# CM_CORE_AON__EVE3 register map
Vendor: Texas Instruments
Peripheral module from a debugger description file (folder TDA2Px).
Registers are 32-bit, access per field, reset 0x3 unless marked. A register's access mark holds for its fields unless they carry their own. Offsets are as the file gives them; lines under a group give offsets from that group; [hi:lo] are bit positions; {n}, {i} and the like mark numbered series; 'fields as' and 'values as' point back to an identical list; <NAME> marks a mode.

## CM_CORE_AON__EVE3
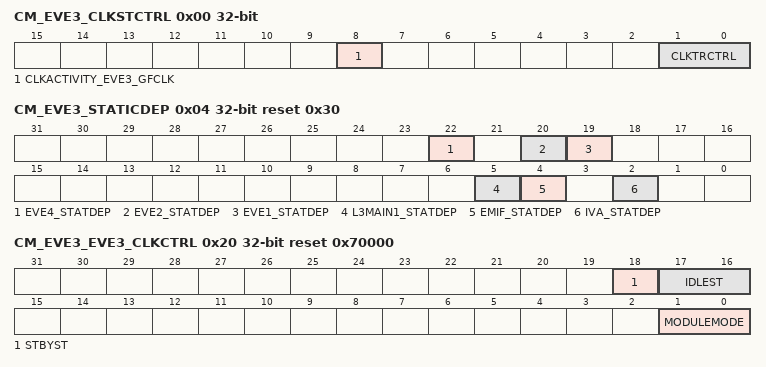
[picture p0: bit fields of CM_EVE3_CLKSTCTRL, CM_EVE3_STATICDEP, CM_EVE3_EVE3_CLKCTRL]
0x00 CM_EVE3_CLKSTCTRL — This register enables the EVE domain power state transition. It controls the HW supervised domain power state transition between ON-ACTIVE and ON-INACTIVE states. It also hold one status bit per clock input of the domain.
  [8] CLKACTIVITY_EVE3_GFCLK ro — This field indicates the state of the EVE3_GFCLK clock in the domain. [warm reset insensitive]EVE3_GFCLK clock is used as one of the source clocks to the ISS module in this family of devices.
    0=INACT (Corresponding clock is definitely gated); 1=ACT (Corresponding clock is running or gating/ungating transition is on-going)
  [1:0] CLKTRCTRL rw — Controls the clock state transition of the DSP clock domain.
    0=NO_SLEEP (NO_SLEEP: Sleep transition cannot be initiated. Wakeup transition may however occur.); 1=SW_SLEEP (SW_SLEEP: Start a software forced sleep transition on the domain.); 2=SW_WKUP (SW_WKUP: Start a software forced wake-up transition on the domain.); 3=HW_AUTO (HW_AUTO: Automatic transition is enabled. Sleep and wakeup transition are based upon hardware conditions.)
0x04 CM_EVE3_STATICDEP reset 0x30 — This register controls the static domain depedencies from EVE3 domain towards 'target' domains. It is relevant only for domain having system initiator(s).EVE3 is not supported in this family of devices.
  [22] EVE4_STATDEP rw — Static dependency towards EVE4 clock domainEVE4 is not supported in this family of devices.
    0=DISABLED (Dependency is disabled); 1=ENABLED (Dependency is enabled)
  [20] EVE2_STATDEP rw — Static dependency towards EVE2 clock domain
    values as EVE4_STATDEP
  [19] EVE1_STATDEP rw — Static dependency towards EVE1 clock domain
    values as EVE4_STATDEP
  [5] L3MAIN1_STATDEP ro — Static dependency towards L3MAIN1 clock domain
    1=ENABLED (Dependency is enabled)
  [4] EMIF_STATDEP rw — Static dependency towards EMIF clock domain
    values as EVE4_STATDEP
  [2] IVA_STATDEP rw — Static dependency towards IVA clock domain
    values as EVE4_STATDEP
0x20 CM_EVE3_EVE3_CLKCTRL reset 0x70000 — This register manages the ISS clocks.
  [18] STBYST ro — Module standby status. [warm reset insensitive]
    0=FUNC (Module is functional (not in standby)); 1=STANDBY (Module is in standby)
  [17:16] IDLEST ro — Module idle status. [warm reset insensitive]
    0=FUNC (Module is fully functional, including OCP); 1=TRANS (Module is performing transition: wakeup, or sleep, or sleep abortion); 2=IDLE (Module is in Idle mode (only OCP part). It is functional if using separate functional clock); 3=DISABLE (Module is disabled and cannot be accessed)
  [1:0] MODULEMODE rw — Control the way mandatory clocks are managed.
    0=DISABLED (Module is disabled by SW. Any OCP access to module results in an error, except if resulting from a module wakeup (asynchronous wakeup).); 1=AUTO (Module is managed automatically by HW according to clock domain transition. A clock domain sleep transition put module into idle. A wakeup domain transition put it back into function. If CLKTRCTRL=3, any OCP access to module is always granted. Module clocks may be gated according to the clock domain state.)
